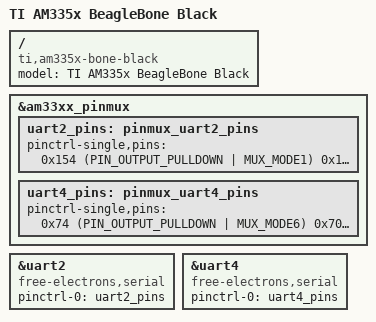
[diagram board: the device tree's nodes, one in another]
/dts-v1/;

#include "am33xx.dtsi"
#include "am335x-bone-common.dtsi"

/ {
       model = "TI AM335x BeagleBone Black";
       compatible = "ti,am335x-bone-black", "ti,am335x-bone", "ti,am33xx";
};

&am33xx_pinmux {
	/* Pins 21 (TX) and 22 (RX) of connector P9 */
	uart2_pins: pinmux_uart2_pins {
		pinctrl-single,pins = <
			0x154 (PIN_OUTPUT_PULLDOWN | MUX_MODE1) /* spi0_d0.uart2_tx, MODE 1 */
			0x150 (PIN_INPUT_PULLUP | MUX_MODE1) /* spi0_sclk.uart2_rx, MODE 1 */
		>;
	};

		/* Pins 11 (RX) and 13 (TX) of connector P9 */
	uart4_pins: pinmux_uart4_pins {
		pinctrl-single,pins = <
			0x74 (PIN_OUTPUT_PULLDOWN | MUX_MODE6) /* gpmc_wpn.uart4_tx, MODE 6 */
			0x70 (PIN_INPUT_PULLUP | MUX_MODE6) /* gpmc_wait0.uart4_rx, MODE 6 */
		>;
	};
};

&uart2 {
	compatible = "free-electrons,serial";
	status = "okay";
	pinctrl-names = "default";
	pinctrl-0 = <&uart2_pins>;
};

&uart4 {
	compatible = "free-electrons,serial";
	status = "okay";
	pinctrl-names = "default";
	pinctrl-0 = <&uart4_pins>;
};
